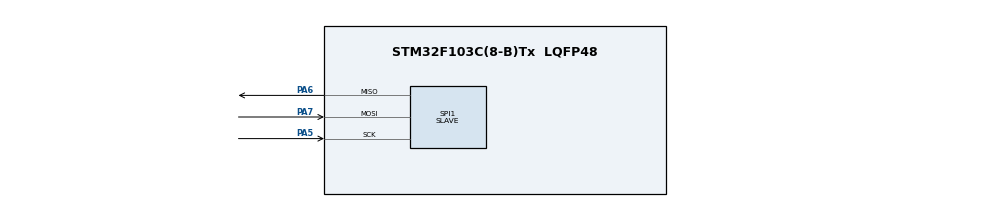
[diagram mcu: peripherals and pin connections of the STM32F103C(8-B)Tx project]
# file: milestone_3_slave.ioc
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Mcu.Family=STM32F1
Mcu.Name=STM32F103C(8-B)Tx
Mcu.Package=LQFP48
NVIC.PriorityGroup=NVIC_PRIORITYGROUP_4
PA13.Mode=Serial_Wire
PA13.Signal=SYS_JTMS-SWDIO
PA14.Mode=Serial_Wire
PA14.Signal=SYS_JTCK-SWCLK
PA5.Mode=Full_Duplex_Slave
PA5.Signal=SPI1_SCK
PA6.Mode=Full_Duplex_Slave
PA6.Signal=SPI1_MISO
PA7.Mode=Full_Duplex_Slave
PA7.Signal=SPI1_MOSI
ProjectManager.HeapSize=0x200
ProjectManager.StackSize=0x400
ProjectManager.TargetToolchain=STM32CubeIDE
RCC.APB1Freq_Value=8000000
RCC.APB2Freq_Value=8000000
SPI1.Direction=SPI_DIRECTION_2LINES
SPI1.Mode=SPI_MODE_SLAVE
SPI1.VirtualType=VM_SLAVE
board=custom

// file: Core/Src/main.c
/* USER CODE BEGIN Header */
/**
  ******************************************************************************
  * @file           : main.c
  * @brief          : Main program body
  ******************************************************************************
  * @attention
  *
  * Copyright (c) 2026 STMicroelectronics.
  * All rights reserved.
  *
  * This software is licensed under terms that can be found in the LICENSE file
  * in the root directory of this software component.
  * If no LICENSE file comes with this software, it is provided AS-IS.
  *
  ******************************************************************************
  */
/* USER CODE END Header */
#include "main.h"

/* USER CODE BEGIN PTD */
	typedef struct
	{
		uint16_t ID;
		float temperature;
		uint16_t humidity;
	} Data;

/* USER CODE END PTD */

SPI_HandleTypeDef hspi1;

void SystemClock_Config(void);
static void MX_GPIO_Init(void);
static void MX_SPI1_Init(void);

int main(void)
{

  /* MCU Configuration--------------------------------------------------------*/

  /* Reset of all peripherals, Initializes the Flash interface and the Systick. */
  HAL_Init();

  /* Configure the system clock */
  SystemClock_Config();

  /* Initialize all configured peripherals */
  MX_GPIO_Init();
  MX_SPI1_Init();
  /* USER CODE BEGIN 2 */

  uint16_t ID_Request = 0x0000;

  float Temp_SEL = 0;
  uint16_t Humidity_SEL = 0;

  uint16_t Raw_Temp;
  uint16_t Raw_Humidity;
  uint32_t DataP;

  uint8_t Dummy_TX[2] = {0};
  uint8_t Dummy_RX[3] = {0};
  uint8_t Bytes_Request[2];
  uint8_t txData[3];

  Data data[5] =
  {
		  {0x1001, 24.5, 65},
  		  {0x1002, 27.2, 50},
  		  {0x1003, 21.8, 85},
  		  {0x1004, 29.0, 40},
  		  {0x1005, 25.0, 60},
  };
  /* USER CODE END 2 */

  /* Infinite loop */
  /* USER CODE BEGIN WHILE */
  while (1)
  {

	        if (HAL_SPI_TransmitReceive(&hspi1, Dummy_TX, Bytes_Request, 2, 500) == HAL_OK)
	        {
	            ID_Request = (Bytes_Request[0] << 8) | Bytes_Request[1];

	            Temp_SEL = 0.0f;
	            Humidity_SEL = 0;

	            for(int i = 0; i < 5; i++)
	            {
	                if (data[i].ID == ID_Request)
	                {
	                    Temp_SEL = data[i].temperature;
	                    Humidity_SEL = data[i].humidity;
	                    break;
	                }
	            }

	            Raw_Temp = (uint16_t)((Temp_SEL * 4095.0f) / 50.0f);
	            Raw_Humidity   = (uint16_t)((Humidity_SEL * 4095.0f) / 100.0f);

	            DataP = (Raw_Temp << 12);
	            DataP |= (Raw_Humidity & 0xFFF);

	            txData[0] = (DataP >> 16) & 0xFF;
	            txData[1] = (DataP >> 8) & 0xFF;
	            txData[2] = DataP & 0xFF;

	            HAL_SPI_TransmitReceive(&hspi1, txData, Dummy_RX, 3, 500);
	        }
  }
    /* USER CODE END WHILE */

}

void SystemClock_Config(void)
{
  RCC_OscInitTypeDef RCC_OscInitStruct = {0};
  RCC_ClkInitTypeDef RCC_ClkInitStruct = {0};

  /** Initializes the RCC Oscillators according to the specified parameters
  * in the RCC_OscInitTypeDef structure.
  */
  RCC_OscInitStruct.OscillatorType = RCC_OSCILLATORTYPE_HSI;
  RCC_OscInitStruct.HSIState = RCC_HSI_ON;
  RCC_OscInitStruct.HSICalibrationValue = RCC_HSICALIBRATION_DEFAULT;
  RCC_OscInitStruct.PLL.PLLState = RCC_PLL_NONE;
  if (HAL_RCC_OscConfig(&RCC_OscInitStruct) != HAL_OK)
  {
    Error_Handler();
  }

  /** Initializes the CPU, AHB and APB buses clocks
  */
  RCC_ClkInitStruct.ClockType = RCC_CLOCKTYPE_HCLK|RCC_CLOCKTYPE_SYSCLK
                              |RCC_CLOCKTYPE_PCLK1|RCC_CLOCKTYPE_PCLK2;
  RCC_ClkInitStruct.SYSCLKSource = RCC_SYSCLKSOURCE_HSI;
  RCC_ClkInitStruct.AHBCLKDivider = RCC_SYSCLK_DIV1;
  RCC_ClkInitStruct.APB1CLKDivider = RCC_HCLK_DIV1;
  RCC_ClkInitStruct.APB2CLKDivider = RCC_HCLK_DIV1;

  if (HAL_RCC_ClockConfig(&RCC_ClkInitStruct, FLASH_LATENCY_0) != HAL_OK)
  {
    Error_Handler();
  }
}

static void MX_SPI1_Init(void)
{

  /* SPI1 parameter configuration*/
  hspi1.Instance = SPI1;
  hspi1.Init.Mode = SPI_MODE_SLAVE;
  hspi1.Init.Direction = SPI_DIRECTION_2LINES;
  hspi1.Init.DataSize = SPI_DATASIZE_8BIT;
  hspi1.Init.CLKPolarity = SPI_POLARITY_LOW;
  hspi1.Init.CLKPhase = SPI_PHASE_1EDGE;
  hspi1.Init.NSS = SPI_NSS_HARD_INPUT;
  hspi1.Init.FirstBit = SPI_FIRSTBIT_MSB;
  hspi1.Init.TIMode = SPI_TIMODE_DISABLE;
  hspi1.Init.CRCCalculation = SPI_CRCCALCULATION_DISABLE;
  hspi1.Init.CRCPolynomial = 10;
  if (HAL_SPI_Init(&hspi1) != HAL_OK)
  {
    Error_Handler();
  }

}

static void MX_GPIO_Init(void)
{
  GPIO_InitTypeDef GPIO_InitStruct = {0};

  /* GPIO Ports Clock Enable */
  __HAL_RCC_GPIOA_CLK_ENABLE();
  __HAL_RCC_GPIOB_CLK_ENABLE();

  /*Configure GPIO pin Output Level */
  HAL_GPIO_WritePin(GPIOB, GPIO_PIN_12, GPIO_PIN_RESET);

  /*Configure GPIO pin : PB12 */
  GPIO_InitStruct.Pin = GPIO_PIN_12;
  GPIO_InitStruct.Mode = GPIO_MODE_OUTPUT_PP;
  GPIO_InitStruct.Pull = GPIO_NOPULL;
  GPIO_InitStruct.Speed = GPIO_SPEED_FREQ_LOW;
  HAL_GPIO_Init(GPIOB, &GPIO_InitStruct);

}

void Error_Handler(void)
{
  __disable_irq();
  while (1)
  {
  }
}
